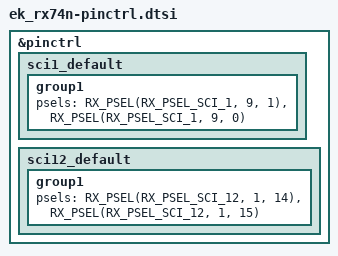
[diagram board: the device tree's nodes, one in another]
/*
 * Copyright (c) 2026 Renesas Electronics Corporation
 * SPDX-License-Identifier: Apache-2.0
 */

&pinctrl {
	sci1_default: sci1_default {
		group1 {
			psels = <RX_PSEL(RX_PSEL_SCI_1, 9, 1)>, /* SDA */
				<RX_PSEL(RX_PSEL_SCI_1, 9, 0)>; /* SCL */
		};
	};

	sci12_default: sci12_default {
		group1 {
			psels = <RX_PSEL(RX_PSEL_SCI_12, 1, 14)>, /* TX */
				<RX_PSEL(RX_PSEL_SCI_12, 1, 15)>; /* RX */
		};
	};
};
